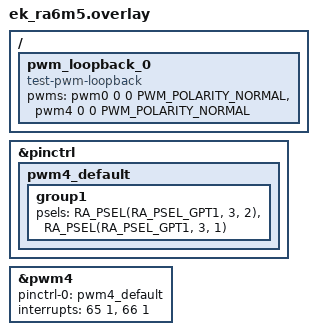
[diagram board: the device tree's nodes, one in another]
/*
 * Copyright (c) 2024 Renesas Electronics Corporation
 *
 * SPDX-License-Identifier: Apache-2.0
 */

#include <zephyr/dt-bindings/pwm/pwm.h>
#include <zephyr/dt-bindings/pwm/ra_pwm.h>

/ {
	pwm_loopback_0 {
		compatible = "test-pwm-loopback";
		/* first index must be a 32-Bit timer */
		pwms = <&pwm0 0 0 PWM_POLARITY_NORMAL>,
		       <&pwm4 0 0 PWM_POLARITY_NORMAL>;
	};
};

&pinctrl {
	pwm4_default: pwm4_default {
		group1 {
			/* GTIOC4A GTIOC4B */
			psels = <RA_PSEL(RA_PSEL_GPT1, 3, 2)>,
				<RA_PSEL(RA_PSEL_GPT1, 3, 1)>;
		};
	};
};

&pwm4 {
	pinctrl-0 = <&pwm4_default>;
	pinctrl-names = "default";
	interrupts = <65 1>, <66 1>;
	interrupt-names = "gtioca", "overflow";
	status = "okay";
};
